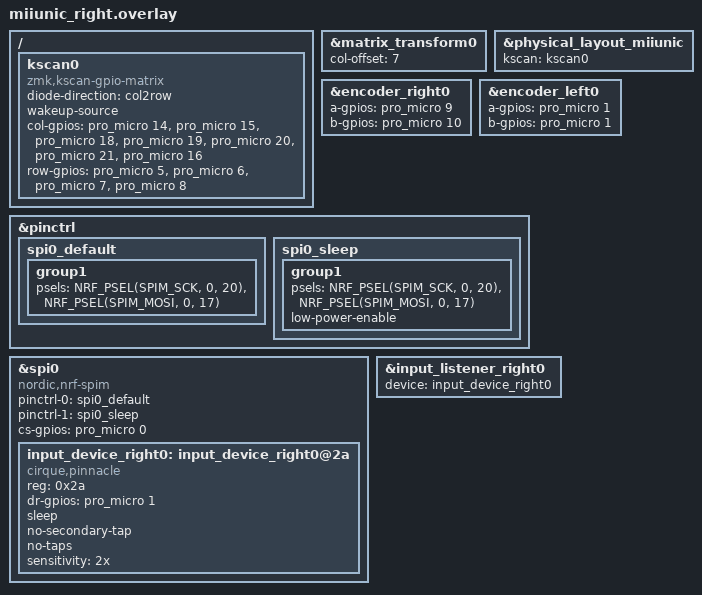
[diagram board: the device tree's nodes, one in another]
#include "miiunic.dtsi"

/ {
    kscan0: kscan0 {
        compatible = "zmk,kscan-gpio-matrix";
        diode-direction = "col2row";
        wakeup-source;

        col-gpios
            = <&pro_micro 14 GPIO_ACTIVE_HIGH>
            , <&pro_micro 15 GPIO_ACTIVE_HIGH>
            , <&pro_micro 18 GPIO_ACTIVE_HIGH>
            , <&pro_micro 19 GPIO_ACTIVE_HIGH>
            , <&pro_micro 20 GPIO_ACTIVE_HIGH>
            , <&pro_micro 21 GPIO_ACTIVE_HIGH>
            , <&pro_micro 16 GPIO_ACTIVE_HIGH>
            ;

        row-gpios
            = <&pro_micro 5 (GPIO_ACTIVE_HIGH | GPIO_PULL_DOWN)>
            , <&pro_micro 6 (GPIO_ACTIVE_HIGH | GPIO_PULL_DOWN)>
            , <&pro_micro 7 (GPIO_ACTIVE_HIGH | GPIO_PULL_DOWN)>
            , <&pro_micro 8 (GPIO_ACTIVE_HIGH | GPIO_PULL_DOWN)>
            ;
    };
};

&matrix_transform0 {
    col-offset = <7>;
};

&physical_layout_miiunic {
    kscan = <&kscan0>;
};
// == Input devices ==
// Enabling input-split for its own input devices
// Adding input devices and assigning them to input-split
/*
&input_split_right0 {
    status = "okay";
    device = <&input_device_right0>;
};
*/

&encoder_right0 {
    a-gpios = <&pro_micro 9 (GPIO_ACTIVE_HIGH | GPIO_PULL_UP)>;
    b-gpios = <&pro_micro 10 (GPIO_ACTIVE_HIGH | GPIO_PULL_UP)>;
    status = "okay";
};

// Assigning dummy pins to other part's encoders
// just to satisfy the devicetree requirements.
// No code will be compiled for these disabled encoders.
&encoder_left0 {
    a-gpios = <&pro_micro 1 (GPIO_ACTIVE_HIGH | GPIO_PULL_UP)>;
    b-gpios = <&pro_micro 1 (GPIO_ACTIVE_HIGH | GPIO_PULL_UP)>;
};

// RIGHT I2C
/*
&pro_micro_i2c {
    status = "okay";
    input_device_right0: input_device_right0@2a {
        status = "okay";
        compatible = "cirque,pinnacle";
        reg = <0x2a>;
        dr-gpios = <&pro_micro 1 (GPIO_ACTIVE_HIGH)>;
        sleep;
        no-secondary-tap;
        no-taps;
        sensitivity = "2x";
    };
};
*/

// SPI RIGHT SPI

/**
 * Generated by Shield Wizard for ZMK
 * Applies to shield "miiunic_left" with board "nice_nano_v2" only
 */

//
// ======== spi0 ========
//

// pin control for spi0
// - SCK on D3
// - MOSI on D2
&pinctrl {
    /* configuration for spi0 device, default state */
    spi0_default: spi0_default {
        group1 {
            psels = <NRF_PSEL(SPIM_SCK, 0, 20)>,
                    <NRF_PSEL(SPIM_MOSI, 0, 17)>;
        };
    };
    /* configuration for spi0 device, sleep state */
    spi0_sleep: spi0_sleep {
        group1 {
            psels = <NRF_PSEL(SPIM_SCK, 0, 20)>,
                    <NRF_PSEL(SPIM_MOSI, 0, 17)>;
            low-power-enable;
        };
    };
};
&spi0 {
  compatible = "nordic,nrf-spim";
  status = "okay";
  pinctrl-0 = <&spi0_default>;
  pinctrl-1 = <&spi0_sleep>;
  pinctrl-names = "default", "sleep";
};

// devices on spi0

// CS pins for devices on spi0
&spi0 {
    status = "okay";
    cs-gpios = <&pro_micro 0 GPIO_ACTIVE_HIGH>;
    input_device_right0: input_device_right0@2a {
        status = "okay";
        compatible = "cirque,pinnacle";
        reg = <0x2a>;
        dr-gpios = <&pro_micro 1 (GPIO_ACTIVE_HIGH)>;
        sleep;
        no-secondary-tap;
        no-taps;
        sensitivity = "2x";
    };
};

&input_listener_right0 {
    device = <&input_device_right0>;
};
